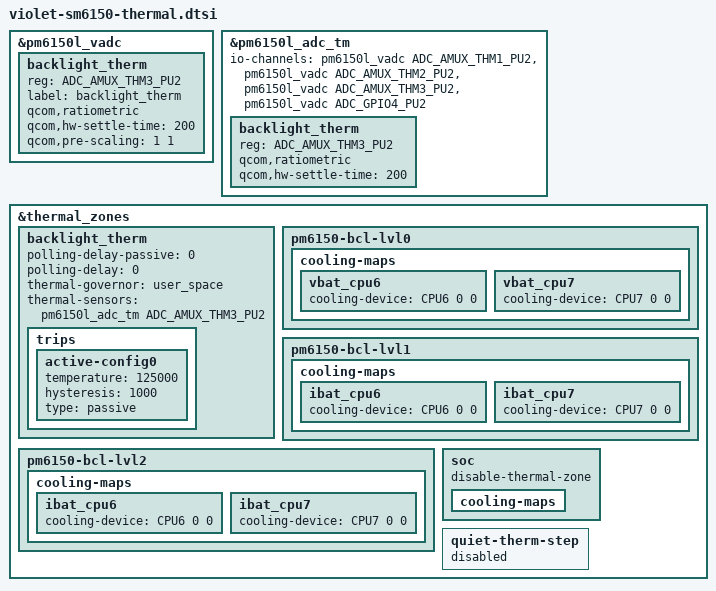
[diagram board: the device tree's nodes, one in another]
/*
 * Copyright (C) 2021 The LineageOS Project
 *
 * this file is for attribution only of violet
 * And public attribution of Xiaomi platforms (like F7B and so)
 */

&pm6150l_vadc {
    /delete-node/ rf_pa1_therm;
    backlight_therm {
        reg = <ADC_AMUX_THM3_PU2>;
        label = "backlight_therm";
        qcom,ratiometric;
        qcom,hw-settle-time = <200>;
        qcom,pre-scaling = <1 1>;
    };
};

&pm6150l_adc_tm {
    io-channels =
        <&pm6150l_vadc ADC_AMUX_THM1_PU2>,
        <&pm6150l_vadc ADC_AMUX_THM2_PU2>,
        <&pm6150l_vadc ADC_AMUX_THM3_PU2>,
        <&pm6150l_vadc ADC_GPIO4_PU2>;

    /delete-node/ camera_flash_therm;
    backlight_therm {
        reg = <ADC_AMUX_THM3_PU2>;
        qcom,ratiometric;
        qcom,hw-settle-time = <200>;
    };
};

&thermal_zones {
    backlight_therm {
        polling-delay-passive = <0>;
        polling-delay = <0>;
        thermal-governor = "user_space";
        thermal-sensors = <&pm6150l_adc_tm ADC_AMUX_THM3_PU2>;
        trips {
            active-config0 {
                temperature = <125000>;
                hysteresis = <1000>;
                type = "passive";
            };
        };
    };

    /*
     * The BCL zones are useful for monitoring, but they used to pin the
     * big cluster to its lowest cooling state as soon as the battery
     * twitched. Keep the zones, drop the clamping: the CPU and PMIC
     * thermal zones still look after the silicon.
     */
    pm6150-bcl-lvl0 {
        cooling-maps {
            vbat_cpu6 {
                cooling-device = <&CPU6 0 0>;
            };
            vbat_cpu7 {
                cooling-device = <&CPU7 0 0>;
            };
        };
    };

    pm6150-bcl-lvl1 {
        cooling-maps {
            ibat_cpu6 {
                cooling-device = <&CPU6 0 0>;
            };
            ibat_cpu7 {
                cooling-device = <&CPU7 0 0>;
            };
        };
    };

    pm6150-bcl-lvl2 {
        cooling-maps {
            ibat_cpu6 {
                cooling-device = <&CPU6 0 0>;
            };
            ibat_cpu7 {
                cooling-device = <&CPU7 0 0>;
            };
        };
    };

    soc {
        disable-thermal-zone;

        cooling-maps {
            /delete-node/ soc_cpu6;
        };
    };

    quiet-therm-step {
        status = "disabled";
    };
};
